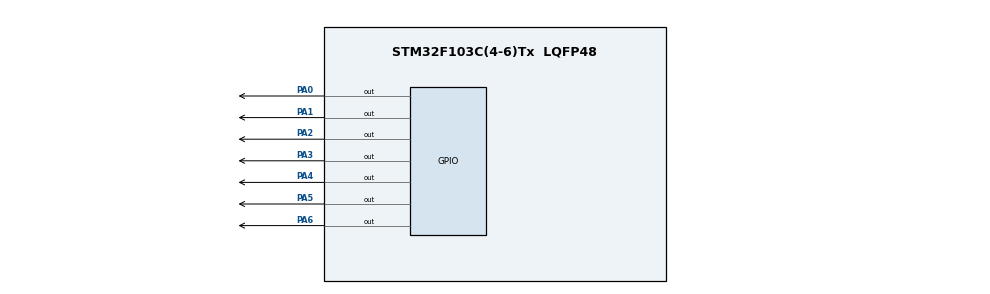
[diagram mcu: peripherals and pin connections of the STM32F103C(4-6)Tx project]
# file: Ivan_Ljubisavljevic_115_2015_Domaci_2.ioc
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Mcu.Family=STM32F1
Mcu.Name=STM32F103C(4-6)Tx
Mcu.Package=LQFP48
NVIC.PriorityGroup=NVIC_PRIORITYGROUP_4
PA0-WKUP.Signal=GPIO_Output
PA1.Signal=GPIO_Output
PA2.Signal=GPIO_Output
PA3.Signal=GPIO_Output
PA4.Signal=GPIO_Output
PA5.Signal=GPIO_Output
PA6.Signal=GPIO_Output
ProjectManager.HeapSize=0x200
ProjectManager.StackSize=0x400
ProjectManager.TargetToolchain=EWARM V8.32
RCC.APB1Freq_Value=8000000
RCC.APB2Freq_Value=8000000
VP_SYS_VS_ND.Mode=No_Debug
board=custom

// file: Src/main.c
/* USER CODE BEGIN Header */
/**
  ******************************************************************************
  * @file           : main.c
  * @brief          : Main program body
  ******************************************************************************
  * @attention
  *
  * <h2><center>&copy; Copyright (c) 2021 STMicroelectronics.
  * All rights reserved.</center></h2>
  *
  * This software component is licensed by ST under BSD 3-Clause license,
  * the "License"; You may not use this file except in compliance with the
  * License. You may obtain a copy of the License at:
  *                        opensource.org/licenses/BSD-3-Clause
  *
  ******************************************************************************
  */
/* USER CODE END Header */

#include "main.h"

/* USER CODE BEGIN Includes */
/*
#define br0 GPIO_PIN_6
#define br1 GPIO_PIN_0|GPIO_PIN_3|GPIO_PIN_4|GPIO_PIN_5|GPIO_PIN_6
#define br2 GPIO_PIN_2|GPIO_PIN_5
#define br3 GPIO_PIN_4|GPIO_PIN_5
#define br4 GPIO_PIN_0|GPIO_PIN_3|GPIO_PIN_4
#define br5 GPIO_PIN_1|GPIO_PIN_4
#define br6 GPIO_PIN_1
#define br7 GPIO_PIN_3|GPIO_PIN_4|GPIO_PIN_5|GPIO_PIN_6
#define br8 GPIO_PIN_7
#define br9 GPIO_PIN_4

2nacin
#define br0 GPIO_PIN_0|GPIO_PIN_1|GPIO_PIN_2|GPIO_PIN_3|GPIO_PIN_4|GPIO_PIN_5
#define br1 GPIO_PIN_1|GPIO_PIN_2
#define br2 GPIO_PIN_0|GPIO_PIN_1|GPIO_PIN_3|GPIO_PIN_4|GPIO_PIN_6
#define br3 GPIO_PIN_0|GPIO_PIN_1|GPIO_PIN_2|GPIO_PIN_3|GPIO_PIN_6
#define br4 GPIO_PIN_1|GPIO_PIN_2|GPIO_PIN_5|GPIO_PIN_6
#define br5 GPIO_PIN_0|GPIO_PIN_2|GPIO_PIN_3|GPIO_PIN_5|GPIO_PIN_6
#define br6 GPIO_PIN_0|GPIO_PIN_2|GPIO_PIN_3|GPIO_PIN_4|GPIO_PIN_5|GPIO_PIN_6
#define br7 GPIO_PIN_0|GPIO_PIN_1|GPIO_PIN_2
#define br8 GPIO_PIN_0|GPIO_PIN_1|GPIO_PIN_2|GPIO_PIN_3|GPIO_PIN_4|GPIO_PIN_5|GPIO_PIN_6
#define br9 GPIO_PIN_0|GPIO_PIN_1|GPIO_PIN_2|GPIO_PIN_3|GPIO_PIN_5|GPIO_PIN_6
*/

#define br0 0x3F
#define br1 0x06
#define br2 0x5B
#define br3 0x4F
#define br4 0x66
#define br5 0x6D
#define br6 0x7D
#define br7 0x07
#define br8 0x7F
#define br9 0x6F

int niz[] = {br0, br1, br2, br3, br4, br5, br6, br7, br8, br9};

/* USER CODE END Includes */

void SystemClock_Config(void);
static void MX_GPIO_Init(void);

int main(void)
{

  /* MCU Configuration--------------------------------------------------------*/

  /* Reset of all peripherals, Initializes the Flash interface and the Systick. */
  HAL_Init();

  /* Configure the system clock */
  SystemClock_Config();               //OVO JE ZAKOMENTARISANO * JA

  /* Initialize all configured peripherals */
  MX_GPIO_Init();

  /* Infinite loop */
  while (1)
  {
      for(int i = 0; i<10; i++)
      {

        GPIOA->ODR=~niz[i];
        HAL_Delay(1000);

/* 2 nacin
        HAL_GPIO_WritePin(GPIOA,niz[i],GPIO_PIN_RESET);
        HAL_Delay(250);
        HAL_GPIO_WritePin(GPIOA,niz[i],GPIO_PIN_SET);
        HAL_Delay(50);
  */

      }

  }
}

void SystemClock_Config(void)
{
  RCC_OscInitTypeDef RCC_OscInitStruct = {0};
  RCC_ClkInitTypeDef RCC_ClkInitStruct = {0};

  /** Initializes the CPU, AHB and APB busses clocks
  */
  RCC_OscInitStruct.OscillatorType = RCC_OSCILLATORTYPE_HSI;
  RCC_OscInitStruct.HSIState = RCC_HSI_ON;
  RCC_OscInitStruct.HSICalibrationValue = RCC_HSICALIBRATION_DEFAULT;
  RCC_OscInitStruct.PLL.PLLState = RCC_PLL_NONE;
  if (HAL_RCC_OscConfig(&RCC_OscInitStruct) != HAL_OK)
  {
    Error_Handler();
  }
  /** Initializes the CPU, AHB and APB busses clocks
  */
  RCC_ClkInitStruct.ClockType = RCC_CLOCKTYPE_HCLK|RCC_CLOCKTYPE_SYSCLK
                              |RCC_CLOCKTYPE_PCLK1|RCC_CLOCKTYPE_PCLK2;
  RCC_ClkInitStruct.SYSCLKSource = RCC_SYSCLKSOURCE_HSI;
  RCC_ClkInitStruct.AHBCLKDivider = RCC_SYSCLK_DIV1;
  RCC_ClkInitStruct.APB1CLKDivider = RCC_HCLK_DIV1;
  RCC_ClkInitStruct.APB2CLKDivider = RCC_HCLK_DIV1;

  if (HAL_RCC_ClockConfig(&RCC_ClkInitStruct, FLASH_LATENCY_0) != HAL_OK)
  {
    Error_Handler();
  }
}

static void MX_GPIO_Init(void)
{
  GPIO_InitTypeDef GPIO_InitStruct = {0};

  /* GPIO Ports Clock Enable */
  __HAL_RCC_GPIOA_CLK_ENABLE();

  /*Configure GPIO pin Output Level */

  HAL_GPIO_WritePin(GPIOA, GPIO_PIN_0, GPIO_PIN_SET);
  HAL_GPIO_WritePin(GPIOA, GPIO_PIN_1, GPIO_PIN_SET);
  HAL_GPIO_WritePin(GPIOA, GPIO_PIN_2, GPIO_PIN_SET);
  HAL_GPIO_WritePin(GPIOA, GPIO_PIN_3, GPIO_PIN_SET);
  HAL_GPIO_WritePin(GPIOA, GPIO_PIN_4, GPIO_PIN_SET);
  HAL_GPIO_WritePin(GPIOA, GPIO_PIN_5, GPIO_PIN_SET);
  HAL_GPIO_WritePin(GPIOA, GPIO_PIN_6, GPIO_PIN_SET);

  /*Configure GPIO pins : PA5 PA6 */
  GPIO_InitStruct.Pin = GPIO_PIN_0 | GPIO_PIN_1 | GPIO_PIN_2 | GPIO_PIN_3 | GPIO_PIN_4 | GPIO_PIN_5 | GPIO_PIN_6;
  GPIO_InitStruct.Mode = GPIO_MODE_OUTPUT_PP;
  GPIO_InitStruct.Pull = GPIO_NOPULL;
  GPIO_InitStruct.Speed = GPIO_SPEED_FREQ_LOW;
  HAL_GPIO_Init(GPIOA, &GPIO_InitStruct);

}

void Error_Handler(void)
{
}

/************************ (C) COPYRIGHT STMicroelectronics *****END OF FILE****/
